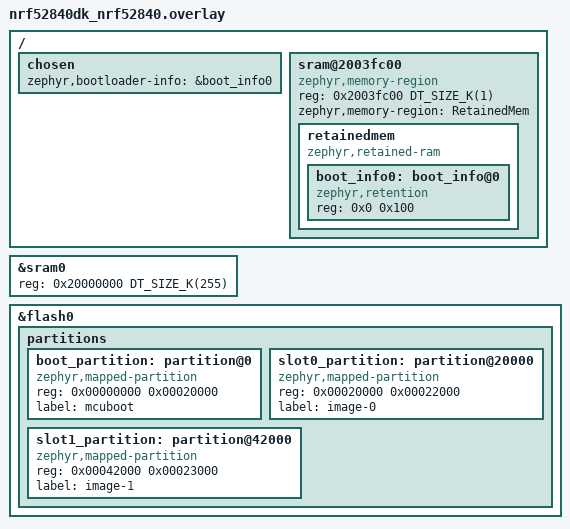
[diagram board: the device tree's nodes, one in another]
/* SPDX-License-Identifier: Apache-2.0 */

/ {
	chosen {
		/delete-property/ zephyr,boot-mode;
	};

	chosen {
		zephyr,bootloader-info = &boot_info0;
	};

	sram@2003fc00 {
		compatible = "zephyr,memory-region", "mmio-sram";
		reg = <0x2003fc00 DT_SIZE_K(1)>;
		zephyr,memory-region = "RetainedMem";
		status = "okay";

		retainedmem {
			compatible = "zephyr,retained-ram";
			#address-cells = <1>;
			#size-cells = <1>;
			status = "okay";

			boot_info0: boot_info@0 {
				compatible = "zephyr,retention";
				reg = <0x0 0x100>;
				status = "okay";
			};
		};
	};
};

/delete-node/ &gpregret1;
/delete-node/ &gpregret2;
/delete-node/ &boot_partition;
/delete-node/ &slot0_partition;
/delete-node/ &slot1_partition;

&sram0 {
	reg = <0x20000000 DT_SIZE_K(255)>;
};

&flash0 {
	partitions {
		boot_partition: partition@0 {
			compatible = "zephyr,mapped-partition";
			reg = <0x00000000 0x00020000>;
			label = "mcuboot";
		};

		slot0_partition: partition@20000 {
			compatible = "zephyr,mapped-partition";
			reg = <0x00020000 0x00022000>;
			label = "image-0";
		};

		slot1_partition: partition@42000 {
			compatible = "zephyr,mapped-partition";
			reg = <0x00042000 0x00023000>;
			label = "image-1";
		};
	};
};
